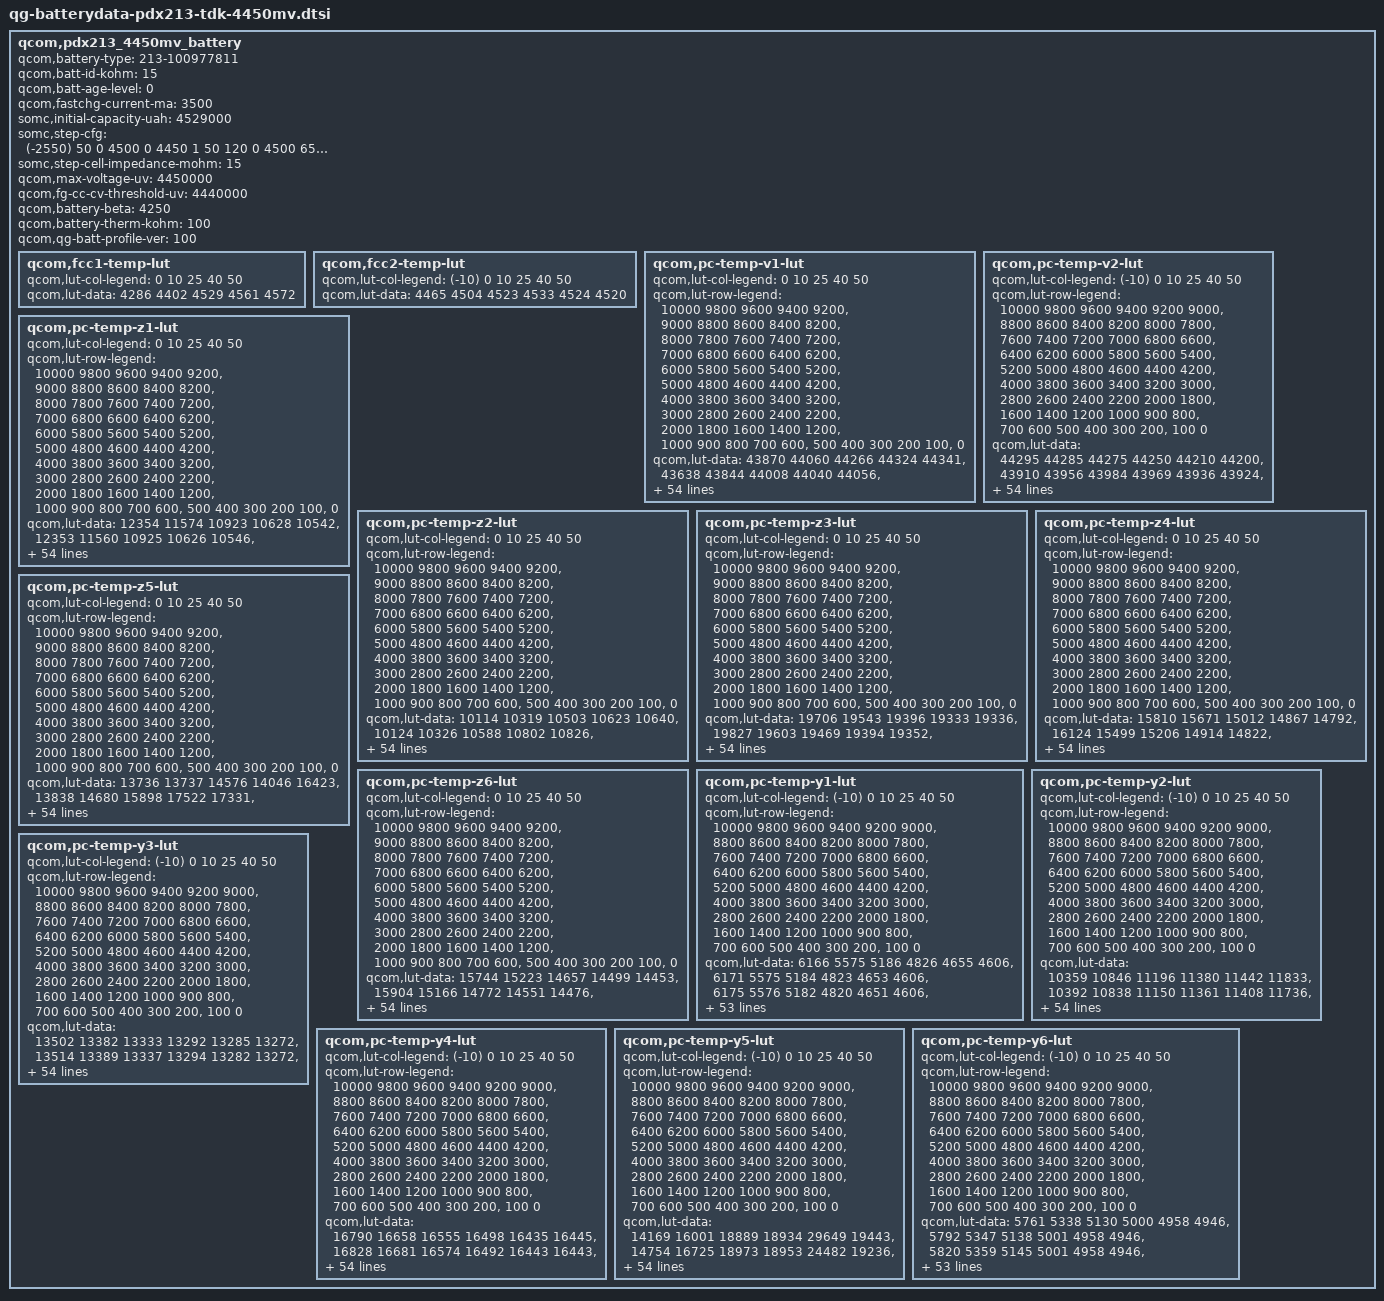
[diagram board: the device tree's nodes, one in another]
qcom,pdx213_4450mv_battery {
	/* Added or Modified by SOMC */
	qcom,battery-type = "213-100977811";
	qcom,batt-id-kohm = <15>;
	qcom,batt-age-level = <0>;
	qcom,fastchg-current-ma = <3500>;
	somc,initial-capacity-uah = <4529000>;
	somc,step-cfg = <
		(-2550) 50    0 4500    0 4450 1
		   50  120    0 4500  650 4450 2
		  120  150    0 4100 2150 4450 3
		  120  150 4100 4200 1750 4450 3
		  120  150 4200 4300 1300 4450 3
		  120  150 4300 4500  850 4450 3
		  150  200    0 4100 2600 4450 3
		  150  200 4100 4200 2150 4450 3
		  150  200 4200 4300 1750 4450 3
		  150  200 4300 4500 1300 4450 3
		  200  450    0 4200 4450 4450 3
		  200  450 4200 4250 3250 4450 3
		  200  450 4250 4350 1950 4450 3
		  200  450 4350 4500 1300 4450 3
		  450  550    0 4500 1300 4200 4
		  550 2550    0 4500    0 4200 5
	>;
	somc,step-cell-impedance-mohm = <15>;

	/* Prepared by Qualcomm */
    /* 4764064_SoMC_Licht_4468mAh_averaged_MasterSlave_Sept10th2020 */
    qcom,max-voltage-uv = <4450000>;
    qcom,fg-cc-cv-threshold-uv = <4440000>;
    /* qcom,fastchg-current-ma = <1500>; */
    /* qcom,batt-id-kohm = <0>; */
    qcom,battery-beta = <4250>;
    qcom,battery-therm-kohm = <100>;
    /* qcom,battery-type = "4764064_SoMC_Licht_4468mAh_averaged_MasterSlave_Sept10th2020"; */
    qcom,qg-batt-profile-ver = <100>;

	qcom,fcc1-temp-lut {
		qcom,lut-col-legend = <0 10 25 40 50>;
		qcom,lut-data = <4286 4402 4529 4561 4572>;
	};

	qcom,fcc2-temp-lut {
		qcom,lut-col-legend = <(-10) 0 10 25 40 50>;
		qcom,lut-data = <4465 4504 4523 4533 4524 4520>;
	};

	qcom,pc-temp-v1-lut {
		qcom,lut-col-legend = <0 10 25 40 50>;
		qcom,lut-row-legend = <10000 9800 9600 9400 9200>,
			<9000 8800 8600 8400 8200>,
			<8000 7800 7600 7400 7200>,
			<7000 6800 6600 6400 6200>,
			<6000 5800 5600 5400 5200>,
			<5000 4800 4600 4400 4200>,
			<4000 3800 3600 3400 3200>,
			<3000 2800 2600 2400 2200>,
			<2000 1800 1600 1400 1200>,
			<1000 900 800 700 600>,
			<500 400 300 200 100>,
			<0>;
		qcom,lut-data = <43870 44060 44266 44324 44341>,
			<43638 43844 44008 44040 44056>,
			<43413 43623 43791 43817 43826>,
			<43187 43398 43582 43607 43615>,
			<42953 43168 43358 43388 43397>,
			<42714 42933 43127 43162 43175>,
			<42478 42694 42891 42931 42948>,
			<42243 42454 42646 42692 42711>,
			<42014 42215 42399 42450 42470>,
			<41794 41976 42157 42208 42229>,
			<41580 41745 41918 41967 41990>,
			<41369 41519 41682 41729 41753>,
			<41157 41299 41450 41498 41521>,
			<40949 41087 41224 41270 41291>,
			<40744 40881 41006 41047 41068>,
			<40539 40679 40795 40830 40850>,
			<40347 40481 40593 40623 40641>,
			<40174 40295 40397 40425 40441>,
			<40014 40131 40212 40237 40250>,
			<39860 39976 40047 40063 40073>,
			<39719 39806 39881 39898 39906>,
			<39572 39621 39671 39704 39717>,
			<39393 39425 39407 39464 39488>,
			<39180 39192 39184 39237 39265>,
			<38993 38950 39021 39056 39077>,
			<38841 38807 38885 38899 38910>,
			<38714 38731 38767 38768 38772>,
			<38628 38666 38666 38657 38660>,
			<38569 38591 38573 38557 38558>,
			<38520 38515 38485 38461 38460>,
			<38473 38445 38407 38374 38370>,
			<38430 38377 38337 38296 38287>,
			<38387 38318 38276 38225 38210>,
			<38343 38267 38220 38161 38140>,
			<38301 38224 38170 38107 38080>,
			<38264 38183 38122 38056 38023>,
			<38230 38149 38076 38003 37957>,
			<38189 38111 38032 37947 37885>,
			<38125 38050 37973 37881 37807>,
			<38040 37958 37891 37800 37727>,
			<37939 37852 37791 37704 37637>,
			<37812 37732 37676 37590 37523>,
			<37667 37592 37540 37453 37383>,
			<37498 37422 37374 37296 37221>,
			<37338 37258 37211 37142 37073>,
			<37228 37147 37096 37034 36974>,
			<37190 37114 37070 37007 36948>,
			<37158 37094 37048 36992 36931>,
			<37130 37071 37033 36975 36915>,
			<37091 37043 37008 36947 36887>,
			<36980 36930 36866 36774 36691>,
			<36582 36519 36466 36364 36279>,
			<36014 35953 35907 35802 35722>,
			<35233 35174 35143 35039 34962>,
			<33896 33885 33973 33871 33803>,
			<30000 30000 30000 30000 30000>;
	};

	qcom,pc-temp-v2-lut {
		qcom,lut-col-legend = <(-10) 0 10 25 40 50>;
		qcom,lut-row-legend = <10000 9800 9600 9400 9200 9000>,
			<8800 8600 8400 8200 8000 7800>,
			<7600 7400 7200 7000 6800 6600>,
			<6400 6200 6000 5800 5600 5400>,
			<5200 5000 4800 4600 4400 4200>,
			<4000 3800 3600 3400 3200 3000>,
			<2800 2600 2400 2200 2000 1800>,
			<1600 1400 1200 1000 900 800>,
			<700 600 500 400 300 200>,
			<100 0>;
		qcom,lut-data = <44295 44285 44275 44250 44210 44200>,
			<43910 43956 43984 43969 43936 43924>,
			<43570 43657 43714 43706 43677 43665>,
			<43284 43395 43469 43465 43437 43426>,
			<43046 43167 43249 43246 43216 43207>,
			<42811 42939 43025 43023 42992 42985>,
			<42555 42694 42787 42785 42758 42751>,
			<42299 42446 42544 42543 42520 42513>,
			<42069 42202 42300 42301 42281 42275>,
			<41864 41959 42054 42059 42040 42034>,
			<41649 41726 41813 41820 41803 41798>,
			<41394 41503 41578 41583 41568 41566>,
			<41129 41287 41349 41351 41338 41338>,
			<40905 41078 41126 41125 41113 41114>,
			<40716 40874 40909 40906 40893 40895>,
			<40505 40661 40701 40693 40682 40683>,
			<40209 40431 40508 40485 40478 40478>,
			<39885 40190 40313 40285 40282 40280>,
			<39632 39944 40097 40103 40097 40096>,
			<39432 39692 39866 39930 39920 39920>,
			<39238 39457 39633 39733 39732 39736>,
			<39024 39246 39391 39494 39525 39535>,
			<38813 39050 39164 39255 39313 39329>,
			<38628 38871 38975 39047 39099 39116>,
			<38455 38706 38809 38855 38886 38899>,
			<38323 38555 38661 38700 38722 38732>,
			<38236 38415 38529 38575 38599 38610>,
			<38169 38286 38410 38465 38494 38504>,
			<38105 38166 38302 38363 38392 38402>,
			<38046 38055 38203 38268 38298 38307>,
			<37989 37978 38110 38181 38213 38220>,
			<37933 37927 38019 38098 38136 38141>,
			<37877 37886 37938 38023 38063 38067>,
			<37818 37848 37870 37958 37996 38000>,
			<37757 37814 37810 37898 37932 37936>,
			<37691 37773 37765 37836 37855 37851>,
			<37621 37726 37732 37772 37763 37735>,
			<37545 37669 37695 37702 37667 37617>,
			<37464 37596 37643 37620 37573 37519>,
			<37377 37505 37578 37531 37478 37426>,
			<37288 37409 37493 37439 37383 37331>,
			<37199 37304 37374 37341 37288 37234>,
			<37112 37172 37240 37221 37172 37118>,
			<37026 37005 37085 37077 37034 36980>,
			<36936 36864 36911 36928 36893 36843>,
			<36840 36761 36822 36876 36853 36803>,
			<36784 36722 36781 36859 36843 36791>,
			<36728 36681 36751 36839 36827 36777>,
			<36664 36635 36701 36814 36803 36753>,
			<36592 36570 36623 36748 36753 36697>,
			<36473 36405 36427 36520 36516 36428>,
			<36241 35989 35970 36028 36026 35942>,
			<35773 35307 35292 35376 35387 35302>,
			<34992 34239 34342 34452 34499 34413>,
			<33721 32619 32836 33194 33238 33170>,
			<31966 29644 29516 29584 29644 29828>;
	};

	qcom,pc-temp-z1-lut {
		qcom,lut-col-legend = <0 10 25 40 50>;
		qcom,lut-row-legend = <10000 9800 9600 9400 9200>,
			<9000 8800 8600 8400 8200>,
			<8000 7800 7600 7400 7200>,
			<7000 6800 6600 6400 6200>,
			<6000 5800 5600 5400 5200>,
			<5000 4800 4600 4400 4200>,
			<4000 3800 3600 3400 3200>,
			<3000 2800 2600 2400 2200>,
			<2000 1800 1600 1400 1200>,
			<1000 900 800 700 600>,
			<500 400 300 200 100>,
			<0>;
		qcom,lut-data = <12354 11574 10923 10628 10542>,
			<12353 11560 10925 10626 10546>,
			<12345 11549 10916 10623 10545>,
			<12335 11541 10908 10619 10544>,
			<12321 11532 10900 10616 10543>,
			<12302 11519 10894 10614 10541>,
			<12284 11499 10888 10612 10540>,
			<12263 11488 10883 10609 10540>,
			<12243 11485 10878 10607 10539>,
			<12225 11483 10873 10605 10538>,
			<12204 11480 10869 10603 10537>,
			<12195 11476 10866 10601 10537>,
			<12199 11471 10864 10601 10536>,
			<12203 11467 10863 10600 10536>,
			<12202 11462 10862 10600 10536>,
			<12192 11459 10861 10601 10537>,
			<12185 11456 10861 10601 10538>,
			<12185 11454 10864 10602 10539>,
			<12186 11457 10866 10603 10540>,
			<12189 11463 10868 10604 10541>,
			<12206 11467 10870 10605 10541>,
			<12225 11473 10873 10607 10542>,
			<12229 11480 10875 10609 10544>,
			<12230 11489 10878 10612 10547>,
			<12228 11499 10883 10616 10550>,
			<12225 11502 10888 10619 10553>,
			<12222 11498 10893 10622 10556>,
			<12226 11495 10898 10625 10558>,
			<12252 11497 10904 10628 10560>,
			<12275 11504 10909 10630 10562>,
			<12275 11510 10914 10633 10564>,
			<12267 11518 10917 10635 10566>,
			<12266 11525 10919 10637 10568>,
			<12272 11526 10922 10639 10570>,
			<12278 11525 10926 10642 10571>,
			<12286 11526 10930 10646 10573>,
			<12299 11532 10936 10649 10575>,
			<12307 11541 10944 10652 10578>,
			<12312 11549 10949 10655 10580>,
			<12321 11559 10953 10658 10581>,
			<12327 11567 10957 10661 10583>,
			<12335 11574 10964 10664 10585>,
			<12351 11582 10972 10666 10587>,
			<12389 11598 10981 10669 10589>,
			<12380 11607 10986 10673 10591>,
			<12394 11612 10988 10675 10592>,
			<12375 11608 10987 10674 10593>,
			<12388 11614 10990 10676 10593>,
			<12414 11615 10994 10676 10594>,
			<12392 11622 10997 10678 10596>,
			<12418 11641 11006 10683 10600>,
			<12468 11656 11020 10691 10607>,
			<12456 11686 11039 10704 10617>,
			<12515 11722 11075 10724 10633>,
			<12515 11722 11075 10724 10633>,
			<12515 11722 11075 10724 10633>;
	};

	qcom,pc-temp-z2-lut {
		qcom,lut-col-legend = <0 10 25 40 50>;
		qcom,lut-row-legend = <10000 9800 9600 9400 9200>,
			<9000 8800 8600 8400 8200>,
			<8000 7800 7600 7400 7200>,
			<7000 6800 6600 6400 6200>,
			<6000 5800 5600 5400 5200>,
			<5000 4800 4600 4400 4200>,
			<4000 3800 3600 3400 3200>,
			<3000 2800 2600 2400 2200>,
			<2000 1800 1600 1400 1200>,
			<1000 900 800 700 600>,
			<500 400 300 200 100>,
			<0>;
		qcom,lut-data = <10114 10319 10503 10623 10640>,
			<10124 10326 10588 10802 10826>,
			<10103 10325 10551 10764 10875>,
			<10082 10294 10521 10736 10852>,
			<10070 10250 10500 10725 10841>,
			<10060 10226 10483 10726 10847>,
			<10055 10207 10479 10730 10851>,
			<10054 10201 10490 10728 10855>,
			<10053 10221 10506 10725 10865>,
			<10082 10253 10619 10832 10862>,
			<10174 10272 10796 11141 10820>,
			<10222 10284 10808 11261 10788>,
			<10173 10297 10655 11200 10753>,
			<10105 10312 10559 11129 10717>,
			<10096 10328 10656 11139 10720>,
			<10109 10344 10808 11183 10736>,
			<10126 10362 10867 11171 10743>,
			<10147 10375 10896 10886 10759>,
			<10171 10381 10907 10651 10779>,
			<10187 10386 10795 10646 10785>,
			<10195 10394 10648 10645 10797>,
			<10202 10409 10648 10665 10826>,
			<10215 10419 10699 10811 10987>,
			<10235 10414 10724 10942 11123>,
			<10255 10403 10682 10979 11094>,
			<10278 10401 10630 11000 11006>,
			<10297 10412 10635 10979 10922>,
			<10302 10422 10672 10841 10832>,
			<10301 10423 10688 10736 10754>,
			<10300 10423 10636 10708 10692>,
			<10301 10424 10579 10691 10646>,
			<10302 10432 10579 10696 10648>,
			<10305 10442 10595 10731 10701>,
			<10312 10453 10615 10769 10758>,
			<10322 10470 10649 10805 10806>,
			<10330 10483 10684 10844 10859>,
			<10336 10491 10703 10887 10944>,
			<10343 10499 10718 10935 11076>,
			<10354 10515 10742 10975 11127>,
			<10365 10537 10792 11016 11100>,
			<10366 10546 10831 11049 11072>,
			<10357 10540 10830 11075 11084>,
			<10354 10536 10823 11103 11114>,
			<10367 10544 10830 11014 11129>,
			<10551 10626 10855 10963 11128>,
			<10413 10678 10873 10981 11112>,
			<10296 10678 10844 10963 11105>,
			<10220 10754 10844 10968 11079>,
			<10022 10876 10806 10960 11119>,
			<9925 11054 10791 11025 11252>,
			<9804 11065 10963 10954 10880>,
			<9727 10951 11005 10765 10725>,
			<9593 10826 10893 10705 10675>,
			<9633 10645 10817 10625 10595>,
			<9633 10645 10817 10625 10595>,
			<9633 10645 10817 10625 10595>;
	};

	qcom,pc-temp-z3-lut {
		qcom,lut-col-legend = <0 10 25 40 50>;
		qcom,lut-row-legend = <10000 9800 9600 9400 9200>,
			<9000 8800 8600 8400 8200>,
			<8000 7800 7600 7400 7200>,
			<7000 6800 6600 6400 6200>,
			<6000 5800 5600 5400 5200>,
			<5000 4800 4600 4400 4200>,
			<4000 3800 3600 3400 3200>,
			<3000 2800 2600 2400 2200>,
			<2000 1800 1600 1400 1200>,
			<1000 900 800 700 600>,
			<500 400 300 200 100>,
			<0>;
		qcom,lut-data = <19706 19543 19396 19333 19336>,
			<19827 19603 19469 19394 19352>,
			<19866 19639 19491 19410 19376>,
			<19883 19658 19499 19417 19384>,
			<19891 19669 19498 19417 19385>,
			<19896 19669 19493 19411 19379>,
			<19896 19662 19488 19405 19373>,
			<19886 19653 19479 19398 19370>,
			<19874 19639 19473 19392 19367>,
			<19868 19624 19473 19392 19365>,
			<19861 19613 19476 19397 19358>,
			<19854 19605 19470 19398 19353>,
			<19833 19598 19448 19388 19348>,
			<19808 19593 19434 19378 19343>,
			<19804 19587 19438 19374 19341>,
			<19805 19581 19444 19373 19340>,
			<19806 19574 19444 19369 19338>,
			<19795 19569 19442 19352 19333>,
			<19771 19566 19439 19339 19328>,
			<19763 19564 19429 19338 19325>,
			<19763 19564 19419 19337 19323>,
			<19765 19569 19423 19339 19322>,
			<19769 19576 19445 19350 19329>,
			<19778 19581 19457 19363 19339>,
			<19783 19587 19438 19372 19357>,
			<19781 19588 19414 19380 19379>,
			<19778 19578 19419 19387 19384>,
			<19774 19569 19445 19393 19376>,
			<19769 19574 19460 19396 19367>,
			<19763 19585 19463 19394 19361>,
			<19757 19588 19464 19389 19355>,
			<19751 19588 19460 19383 19350>,
			<19746 19586 19449 19376 19346>,
			<19743 19582 19441 19369 19341>,
			<19740 19575 19436 19362 19334>,
			<19735 19568 19431 19356 19328>,
			<19729 19563 19428 19352 19328>,
			<19723 19557 19425 19350 19329>,
			<19716 19553 19422 19348 19330>,
			<19709 19548 19419 19348 19327>,
			<19700 19543 19415 19349 19325>,
			<19689 19537 19410 19349 19326>,
			<19674 19529 19406 19350 19329>,
			<19651 19521 19403 19344 19335>,
			<19560 19497 19396 19337 19333>,
			<19422 19474 19387 19336 19319>,
			<19354 19468 19381 19336 19316>,
			<19330 19434 19384 19328 19316>,
			<19296 19386 19375 19327 19314>,
			<19290 19328 19368 19323 19302>,
			<19267 19325 19358 19339 19335>,
			<19268 19328 19351 19349 19340>,
			<19277 19322 19351 19356 19340>,
			<19316 19327 19360 19359 19344>,
			<19316 19327 19360 19359 19344>,
			<19316 19327 19360 19359 19344>;
	};

	qcom,pc-temp-z4-lut {
		qcom,lut-col-legend = <0 10 25 40 50>;
		qcom,lut-row-legend = <10000 9800 9600 9400 9200>,
			<9000 8800 8600 8400 8200>,
			<8000 7800 7600 7400 7200>,
			<7000 6800 6600 6400 6200>,
			<6000 5800 5600 5400 5200>,
			<5000 4800 4600 4400 4200>,
			<4000 3800 3600 3400 3200>,
			<3000 2800 2600 2400 2200>,
			<2000 1800 1600 1400 1200>,
			<1000 900 800 700 600>,
			<500 400 300 200 100>,
			<0>;
		qcom,lut-data = <15810 15671 15012 14867 14792>,
			<16124 15499 15206 14914 14822>,
			<15890 15353 15110 14895 14825>,
			<15634 15224 14993 14841 14786>,
			<15479 15116 14921 14808 14764>,
			<15350 15036 14864 14785 14753>,
			<15250 14971 14834 14770 14745>,
			<15174 14926 14820 14762 14738>,
			<15109 14898 14807 14757 14732>,
			<15034 14878 14782 14743 14727>,
			<14952 14863 14754 14719 14721>,
			<14912 14852 14747 14706 14717>,
			<14916 14841 14756 14702 14712>,
			<14926 14830 14759 14699 14705>,
			<14926 14821 14742 14691 14697>,
			<14921 14821 14718 14680 14687>,
			<14918 14829 14709 14676 14679>,
			<14917 14834 14703 14684 14673>,
			<14917 14818 14700 14692 14668>,
			<14914 14790 14702 14687 14663>,
			<14888 14786 14709 14680 14658>,
			<14859 14803 14732 14685 14661>,
			<14874 14832 14801 14745 14713>,
			<14941 14898 14858 14795 14759>,
			<14999 14991 14893 14799 14755>,
			<15034 15014 14916 14797 14740>,
			<15060 14984 14904 14788 14729>,
			<15063 14945 14853 14761 14720>,
			<15045 14914 14814 14737 14713>,
			<15021 14884 14791 14723 14705>,
			<15000 14868 14775 14713 14698>,
			<14979 14860 14768 14705 14690>,
			<14962 14855 14763 14699 14682>,
			<14948 14851 14760 14697 14677>,
			<14936 14848 14758 14696 14675>,
			<14924 14844 14757 14696 14673>,
			<14912 14837 14758 14700 14678>,
			<14900 14830 14762 14712 14695>,
			<14890 14826 14766 14719 14703>,
			<14879 14824 14772 14723 14702>,
			<14865 14820 14776 14725 14700>,
			<14846 14801 14766 14720 14696>,
			<14826 14778 14748 14711 14689>,
			<14805 14761 14740 14715 14689>,
			<14794 14728 14723 14713 14688>,
			<14905 14710 14705 14697 14685>,
			<14974 14706 14695 14687 14678>,
			<14992 14725 14674 14674 14660>,
			<15019 14768 14663 14651 14640>,
			<15017 14828 14661 14647 14641>,
			<15037 14832 14691 14658 14640>,
			<15051 14841 14709 14655 14642>,
			<15054 14853 14710 14649 14643>,
			<15032 14854 14698 14647 14640>,
			<15032 14854 14698 14647 14640>,
			<15032 14854 14698 14647 14640>;
	};

	qcom,pc-temp-z5-lut {
		qcom,lut-col-legend = <0 10 25 40 50>;
		qcom,lut-row-legend = <10000 9800 9600 9400 9200>,
			<9000 8800 8600 8400 8200>,
			<8000 7800 7600 7400 7200>,
			<7000 6800 6600 6400 6200>,
			<6000 5800 5600 5400 5200>,
			<5000 4800 4600 4400 4200>,
			<4000 3800 3600 3400 3200>,
			<3000 2800 2600 2400 2200>,
			<2000 1800 1600 1400 1200>,
			<1000 900 800 700 600>,
			<500 400 300 200 100>,
			<0>;
		qcom,lut-data = <13736 13737 14576 14046 16423>,
			<13838 14680 15898 17522 17331>,
			<14275 15516 16641 18365 19300>,
			<14786 16262 17216 19151 20652>,
			<15295 16931 17959 19641 21293>,
			<15854 17512 18677 20175 21458>,
			<16391 18031 18976 20456 21409>,
			<16857 18511 19175 20148 21380>,
			<17383 19082 19321 19749 21484>,
			<18355 19563 20155 20391 21522>,
			<19896 19765 21506 22485 21124>,
			<20737 20061 21513 23317 20774>,
			<20735 20361 19995 22606 20431>,
			<20654 20851 19007 21780 20208>,
			<21143 21373 20240 22388 20749>,
			<23301 21430 22310 24108 21823>,
			<24949 21259 23274 24388 22266>,
			<24083 21145 23969 21198 22052>,
			<22131 21561 24497 18494 21820>,
			<21516 22605 24262 18757 22131>,
			<23565 24198 23908 19696 23012>,
			<26841 27507 26062 20826 23300>,
			<30407 29762 33027 22619 22765>,
			<34879 29569 36472 23760 22103>,
			<37018 28937 28793 21749 21403>,
			<36079 27986 19227 18200 20514>,
			<34288 24933 18445 17645 20248>,
			<32703 22447 19692 18904 20166>,
			<30914 23028 21262 20424 20135>,
			<29555 24953 23634 21838 20404>,
			<28998 26934 25960 23307 21058>,
			<28625 29288 27126 24705 22025>,
			<28556 31103 27973 26109 23744>,
			<29236 31620 28865 27207 25109>,
			<30075 31925 30351 28114 26021>,
			<30355 31957 31538 28700 26646>,
			<30492 31635 31740 28341 26594>,
			<30649 31292 31649 26879 26136>,
			<30969 31225 31151 25550 25461>,
			<31309 31208 28877 24228 23738>,
			<31196 31157 26767 23344 22232>,
			<29718 30497 26312 23555 22596>,
			<28093 29686 26000 23989 23609>,
			<26484 29069 25031 21355 24060>,
			<21192 29332 24790 19653 22600>,
			<14877 26855 25358 19952 18694>,
			<12333 25131 24325 20999 18708>,
			<11975 18607 27531 20825 20590>,
			<11599 15941 25277 24675 25560>,
			<11535 12637 23634 24698 21719>,
			<11341 12601 18702 22177 28754>,
			<11316 12613 16049 22989 28509>,
			<11294 12341 15668 25424 26528>,
			<11921 12594 16295 25418 27773>,
			<11921 12594 16295 25418 27773>,
			<11921 12594 16295 25418 27773>;
	};

	qcom,pc-temp-z6-lut {
		qcom,lut-col-legend = <0 10 25 40 50>;
		qcom,lut-row-legend = <10000 9800 9600 9400 9200>,
			<9000 8800 8600 8400 8200>,
			<8000 7800 7600 7400 7200>,
			<7000 6800 6600 6400 6200>,
			<6000 5800 5600 5400 5200>,
			<5000 4800 4600 4400 4200>,
			<4000 3800 3600 3400 3200>,
			<3000 2800 2600 2400 2200>,
			<2000 1800 1600 1400 1200>,
			<1000 900 800 700 600>,
			<500 400 300 200 100>,
			<0>;
		qcom,lut-data = <15744 15223 14657 14499 14453>,
			<15904 15166 14772 14551 14476>,
			<15798 15111 14738 14548 14487>,
			<15678 15056 14695 14531 14477>,
			<15594 15004 14663 14517 14468>,
			<15519 14961 14634 14504 14460>,
			<15455 14923 14615 14494 14454>,
			<15401 14893 14603 14486 14449>,
			<15353 14869 14593 14480 14445>,
			<15308 14850 14582 14473 14440>,
			<15264 14836 14572 14467 14435>,
			<15237 14824 14563 14460 14429>,
			<15224 14814 14555 14453 14424>,
			<15215 14804 14548 14446 14419>,
			<15210 14796 14542 14441 14414>,
			<15207 14793 14536 14435 14409>,
			<15204 14792 14532 14431 14404>,
			<15197 14791 14528 14426 14399>,
			<15188 14783 14526 14421 14394>,
			<15179 14771 14523 14418 14391>,
			<15171 14770 14521 14415 14387>,
			<15166 14781 14531 14418 14388>,
			<15175 14800 14577 14451 14414>,
			<15212 14834 14604 14480 14441>,
			<15242 14878 14608 14488 14450>,
			<15258 14889 14610 14493 14455>,
			<15268 14872 14608 14492 14455>,
			<15270 14853 14601 14485 14448>,
			<15262 14845 14594 14477 14440>,
			<15253 14839 14588 14470 14433>,
			<15244 14836 14582 14463 14427>,
			<15235 14834 14575 14457 14421>,
			<15227 14833 14568 14451 14415>,
			<15222 14830 14564 14446 14410>,
			<15217 14827 14560 14441 14405>,
			<15213 14823 14558 14438 14401>,
			<15208 14820 14558 14439 14403>,
			<15207 14817 14560 14442 14411>,
			<15209 14817 14561 14445 14415>,
			<15212 14817 14562 14447 14413>,
			<15212 14817 14563 14448 14412>,
			<15208 14811 14558 14447 14411>,
			<15202 14804 14550 14444 14410>,
			<15193 14799 14547 14442 14413>,
			<15155 14782 14538 14438 14412>,
			<15143 14767 14527 14431 14403>,
			<15141 14763 14519 14427 14399>,
			<15140 14756 14513 14417 14391>,
			<15140 14753 14504 14407 14382>,
			<15147 14753 14501 14403 14376>,
			<15157 14762 14511 14418 14393>,
			<15180 14776 14519 14423 14398>,
			<15203 14789 14524 14427 14401>,
			<15243 14812 14531 14431 14405>,
			<15243 14812 14531 14431 14405>,
			<15243 14812 14531 14431 14405>;
	};

	qcom,pc-temp-y1-lut {
		qcom,lut-col-legend = <(-10) 0 10 25 40 50>;
		qcom,lut-row-legend = <10000 9800 9600 9400 9200 9000>,
			<8800 8600 8400 8200 8000 7800>,
			<7600 7400 7200 7000 6800 6600>,
			<6400 6200 6000 5800 5600 5400>,
			<5200 5000 4800 4600 4400 4200>,
			<4000 3800 3600 3400 3200 3000>,
			<2800 2600 2400 2200 2000 1800>,
			<1600 1400 1200 1000 900 800>,
			<700 600 500 400 300 200>,
			<100 0>;
		qcom,lut-data = <6166 5575 5186 4826 4655 4606>,
			<6171 5575 5184 4823 4653 4606>,
			<6175 5576 5182 4820 4651 4606>,
			<6176 5577 5179 4817 4649 4605>,
			<6177 5579 5176 4813 4648 4605>,
			<6178 5581 5173 4811 4646 4605>,
			<6175 5587 5169 4808 4645 4604>,
			<6171 5594 5166 4805 4644 4604>,
			<6170 5592 5165 4802 4643 4603>,
			<6177 5577 5166 4800 4642 4603>,
			<6181 5569 5166 4797 4642 4603>,
			<6174 5569 5166 4796 4640 4603>,
			<6164 5571 5165 4794 4639 4603>,
			<6165 5574 5162 4793 4639 4603>,
			<6180 5582 5154 4792 4639 4602>,
			<6190 5587 5151 4791 4639 4601>,
			<6192 5587 5152 4791 4639 4601>,
			<6193 5587 5153 4792 4639 4601>,
			<6192 5587 5153 4792 4640 4602>,
			<6182 5587 5152 4792 4640 4603>,
			<6174 5588 5152 4792 4640 4604>,
			<6184 5589 5153 4794 4641 4604>,
			<6198 5591 5155 4797 4642 4604>,
			<6200 5593 5157 4799 4643 4605>,
			<6192 5599 5161 4801 4644 4607>,
			<6187 5601 5164 4803 4646 4608>,
			<6186 5598 5170 4805 4647 4608>,
			<6186 5594 5174 4808 4649 4608>,
			<6184 5594 5174 4811 4650 4609>,
			<6176 5592 5173 4815 4651 4610>,
			<6170 5592 5173 4818 4652 4612>,
			<6168 5592 5175 4822 4655 4612>,
			<6166 5593 5178 4825 4657 4613>,
			<6168 5595 5180 4828 4659 4615>,
			<6178 5598 5182 4831 4660 4617>,
			<6185 5600 5184 4834 4662 4619>,
			<6180 5601 5186 4837 4663 4620>,
			<6171 5601 5188 4839 4664 4621>,
			<6172 5605 5191 4841 4666 4622>,
			<6183 5612 5196 4844 4667 4623>,
			<6191 5614 5202 4847 4669 4624>,
			<6184 5611 5210 4852 4670 4624>,
			<6178 5610 5213 4856 4671 4625>,
			<6182 5609 5214 4860 4673 4626>,
			<6198 5614 5221 4863 4675 4627>,
			<6243 5628 5228 4865 4676 4627>,
			<6233 5631 5239 4868 4676 4629>,
			<6253 5632 5239 4872 4677 4629>,
			<6290 5645 5233 4876 4679 4630>,
			<6346 5656 5241 4878 4679 4630>,
			<6365 5695 5248 4879 4680 4631>,
			<6425 5731 5251 4888 4683 4634>,
			<6512 5777 5270 4906 4689 4638>,
			<6633 5915 5334 4929 4697 4645>,
			<6633 5915 5334 4929 4697 4645>,
			<6633 5915 5334 4929 4697 4645>;
	};

	qcom,pc-temp-y2-lut {
		qcom,lut-col-legend = <(-10) 0 10 25 40 50>;
		qcom,lut-row-legend = <10000 9800 9600 9400 9200 9000>,
			<8800 8600 8400 8200 8000 7800>,
			<7600 7400 7200 7000 6800 6600>,
			<6400 6200 6000 5800 5600 5400>,
			<5200 5000 4800 4600 4400 4200>,
			<4000 3800 3600 3400 3200 3000>,
			<2800 2600 2400 2200 2000 1800>,
			<1600 1400 1200 1000 900 800>,
			<700 600 500 400 300 200>,
			<100 0>;
		qcom,lut-data = <10359 10846 11196 11380 11442 11833>,
			<10392 10838 11150 11361 11408 11736>,
			<10434 10828 11104 11335 11374 11621>,
			<10477 10816 11061 11303 11342 11505>,
			<10514 10803 11021 11268 11314 11409>,
			<10538 10792 10986 11231 11293 11351>,
			<10551 10776 10953 11179 11279 11320>,
			<10562 10762 10925 11134 11267 11298>,
			<10579 10762 10905 11126 11256 11289>,
			<10629 10774 10888 11125 11242 11279>,
			<10666 10785 10882 11125 11237 11269>,
			<10699 10793 10893 11127 11248 11260>,
			<10743 10803 10911 11131 11261 11255>,
			<10746 10837 10928 11141 11261 11266>,
			<10726 10924 10949 11162 11255 11303>,
			<10720 10978 10976 11191 11254 11333>,
			<10759 10991 11028 11238 11291 11351>,
			<10811 10995 11086 11293 11353 11371>,
			<10829 11002 11132 11344 11421 11404>,
			<10837 11024 11175 11395 11506 11459>,
			<10838 11041 11195 11409 11588 11536>,
			<10658 11051 11198 11396 11680 11699>,
			<10341 11058 11201 11384 11739 11830>,
			<10180 11064 11212 11389 11694 11786>,
			<9891 11073 11233 11405 11575 11658>,
			<9713 11075 11248 11422 11529 11616>,
			<9697 11054 11258 11447 11544 11639>,
			<9688 11031 11267 11473 11571 11677>,
			<9682 11049 11284 11495 11595 11733>,
			<9679 11102 11303 11516 11623 11819>,
			<9676 11120 11307 11541 11661 11903>,
			<9673 11082 11297 11577 11736 11993>,
			<9671 11025 11286 11600 11816 12070>,
			<9669 10973 11283 11607 11894 12139>,
			<9668 10916 11280 11613 11964 12202>,
			<9666 10832 11270 11616 11969 12190>,
			<9665 10577 11236 11616 11905 12024>,
			<9665 10319 11194 11613 11841 11900>,
			<9664 10112 11156 11590 11782 11897>,
			<9663 9812 11113 11553 11722 11904>,
			<9662 9710 11056 11525 11709 11891>,
			<9662 9691 10977 11503 11707 11853>,
			<9661 9679 10887 11478 11719 11835>,
			<9660 9672 10785 11443 11732 11825>,
			<9659 9668 10623 11386 11681 11785>,
			<9658 9665 10582 11357 11543 11571>,
			<9657 9663 10296 11324 11507 11518>,
			<9655 9661 10125 11308 11473 11466>,
			<9653 9659 9861 11285 11443 11382>,
			<9651 9657 9756 11243 11492 11508>,
			<9650 9654 9696 11209 11471 11436>,
			<9649 9651 9672 11125 11341 11304>,
			<9648 9649 9659 11023 11253 11221>,
			<9648 9649 9657 10893 11168 11100>,
			<9648 9649 9657 10893 11168 11100>,
			<9648 9649 9657 10893 11168 11100>;
	};

	qcom,pc-temp-y3-lut {
		qcom,lut-col-legend = <(-10) 0 10 25 40 50>;
		qcom,lut-row-legend = <10000 9800 9600 9400 9200 9000>,
			<8800 8600 8400 8200 8000 7800>,
			<7600 7400 7200 7000 6800 6600>,
			<6400 6200 6000 5800 5600 5400>,
			<5200 5000 4800 4600 4400 4200>,
			<4000 3800 3600 3400 3200 3000>,
			<2800 2600 2400 2200 2000 1800>,
			<1600 1400 1200 1000 900 800>,
			<700 600 500 400 300 200>,
			<100 0>;
		qcom,lut-data = <13502 13382 13333 13292 13285 13272>,
			<13514 13389 13337 13294 13282 13272>,
			<13525 13397 13340 13295 13279 13272>,
			<13536 13406 13344 13297 13278 13273>,
			<13544 13413 13347 13299 13278 13273>,
			<13546 13417 13349 13300 13278 13274>,
			<13544 13419 13352 13300 13280 13275>,
			<13541 13420 13354 13300 13284 13276>,
			<13542 13420 13354 13301 13286 13276>,
			<13554 13419 13354 13302 13287 13277>,
			<13561 13418 13354 13303 13287 13278>,
			<13532 13422 13354 13303 13288 13281>,
			<13487 13427 13354 13303 13289 13284>,
			<13479 13424 13353 13304 13289 13284>,
			<13486 13410 13351 13307 13288 13285>,
			<13491 13401 13350 13308 13288 13285>,
			<13483 13403 13350 13307 13291 13285>,
			<13467 13405 13350 13305 13293 13284>,
			<13456 13401 13349 13305 13293 13284>,
			<13448 13391 13347 13306 13292 13286>,
			<13443 13382 13344 13306 13291 13286>,
			<13439 13377 13339 13304 13289 13285>,
			<13435 13372 13333 13302 13288 13283>,
			<13429 13368 13330 13298 13284 13279>,
			<13418 13364 13327 13295 13280 13274>,
			<13412 13360 13325 13293 13278 13273>,
			<13417 13358 13323 13292 13278 13274>,
			<13428 13356 13322 13292 13278 13274>,
			<13443 13347 13321 13292 13277 13274>,
			<13465 13331 13321 13293 13276 13273>,
			<13492 13326 13320 13293 13276 13273>,
			<13521 13330 13319 13292 13276 13273>,
			<13556 13336 13318 13292 13277 13274>,
			<13595 13344 13317 13292 13278 13274>,
			<13642 13353 13316 13292 13279 13275>,
			<13693 13361 13316 13292 13279 13275>,
			<13747 13367 13320 13293 13278 13273>,
			<13806 13373 13325 13294 13277 13272>,
			<13866 13384 13328 13292 13276 13272>,
			<13930 13403 13330 13290 13276 13272>,
			<13996 13426 13333 13290 13276 13273>,
			<14067 13458 13334 13291 13277 13274>,
			<14142 13497 13337 13292 13277 13275>,
			<14223 13547 13339 13292 13277 13276>,
			<14332 13622 13340 13292 13274 13271>,
			<14380 13667 13342 13294 13278 13274>,
			<14530 13755 13343 13295 13282 13276>,
			<14814 13867 13356 13298 13284 13281>,
			<15286 14028 13370 13306 13288 13283>,
			<16090 14279 13408 13311 13291 13284>,
			<17588 14848 13472 13310 13287 13281>,
			<21117 16276 13592 13308 13285 13281>,
			<31980 20965 13983 13318 13287 13282>,
			<65535 41282 15648 13327 13291 13285>,
			<65535 41282 15648 13327 13291 13285>,
			<65535 41282 15648 13327 13291 13285>;
	};

	qcom,pc-temp-y4-lut {
		qcom,lut-col-legend = <(-10) 0 10 25 40 50>;
		qcom,lut-row-legend = <10000 9800 9600 9400 9200 9000>,
			<8800 8600 8400 8200 8000 7800>,
			<7600 7400 7200 7000 6800 6600>,
			<6400 6200 6000 5800 5600 5400>,
			<5200 5000 4800 4600 4400 4200>,
			<4000 3800 3600 3400 3200 3000>,
			<2800 2600 2400 2200 2000 1800>,
			<1600 1400 1200 1000 900 800>,
			<700 600 500 400 300 200>,
			<100 0>;
		qcom,lut-data = <16790 16658 16555 16498 16435 16445>,
			<16828 16681 16574 16492 16443 16443>,
			<16910 16722 16594 16489 16448 16442>,
			<17007 16768 16613 16487 16451 16442>,
			<17087 16806 16626 16487 16452 16441>,
			<17122 16823 16631 16487 16453 16441>,
			<17122 16825 16627 16489 16450 16442>,
			<17122 16827 16621 16491 16447 16443>,
			<17122 16830 16621 16494 16447 16444>,
			<17126 16836 16622 16497 16450 16447>,
			<17131 16841 16625 16501 16454 16448>,
			<17166 16847 16634 16508 16458 16449>,
			<17221 16855 16649 16516 16463 16449>,
			<17236 16880 16665 16524 16470 16451>,
			<17219 16946 16684 16531 16478 16456>,
			<17189 16978 16706 16540 16486 16463>,
			<17089 16943 16740 16560 16492 16470>,
			<16953 16886 16765 16583 16498 16479>,
			<16897 16837 16757 16610 16513 16489>,
			<16873 16785 16722 16638 16539 16501>,
			<16849 16744 16683 16644 16548 16509>,
			<16806 16713 16635 16605 16545 16515>,
			<16764 16687 16593 16556 16540 16518>,
			<16752 16663 16569 16519 16515 16501>,
			<16750 16642 16553 16487 16467 16459>,
			<16751 16621 16544 16479 16452 16444>,
			<16759 16592 16539 16480 16454 16446>,
			<16770 16569 16536 16483 16458 16447>,
			<16772 16567 16535 16486 16464 16452>,
			<16769 16568 16534 16493 16474 16461>,
			<16768 16571 16531 16499 16484 16470>,
			<16769 16575 16521 16506 16494 16478>,
			<16771 16579 16512 16514 16503 16487>,
			<16772 16586 16511 16524 16509 16496>,
			<16775 16598 16512 16533 16514 16503>,
			<16777 16614 16517 16534 16512 16502>,
			<16777 16645 16535 16526 16498 16482>,
			<16777 16676 16556 16516 16483 16465>,
			<16778 16699 16577 16500 16471 16459>,
			<16778 16718 16597 16486 16463 16456>,
			<16779 16723 16601 16485 16461 16456>,
			<16783 16720 16602 16489 16463 16456>,
			<16790 16712 16603 16494 16463 16455>,
			<16798 16683 16603 16497 16463 16452>,
			<16814 16670 16583 16476 16445 16435>,
			<16787 16661 16569 16476 16447 16439>,
			<16820 16668 16595 16490 16453 16447>,
			<16887 16688 16623 16506 16462 16450>,
			<16996 16723 16664 16523 16477 16481>,
			<17188 16767 16710 16547 16518 16530>,
			<17550 16898 16744 16540 16493 16475>,
			<18402 17269 16744 16519 16451 16446>,
			<21794 19369 16835 16543 16459 16452>,
			<56069 43004 18161 16593 16484 16475>,
			<56069 43004 18161 16593 16484 16475>,
			<56069 43004 18161 16593 16484 16475>;
	};

	qcom,pc-temp-y5-lut {
		qcom,lut-col-legend = <(-10) 0 10 25 40 50>;
		qcom,lut-row-legend = <10000 9800 9600 9400 9200 9000>,
			<8800 8600 8400 8200 8000 7800>,
			<7600 7400 7200 7000 6800 6600>,
			<6400 6200 6000 5800 5600 5400>,
			<5200 5000 4800 4600 4400 4200>,
			<4000 3800 3600 3400 3200 3000>,
			<2800 2600 2400 2200 2000 1800>,
			<1600 1400 1200 1000 900 800>,
			<700 600 500 400 300 200>,
			<100 0>;
		qcom,lut-data = <14169 16001 18889 18934 29649 19443>,
			<14754 16725 18973 18953 24482 19236>,
			<15565 17359 18999 18857 20687 18941>,
			<16427 17862 18980 18666 18141 18624>,
			<17162 18191 18929 18399 16723 18347>,
			<17591 18303 18860 18072 16319 18173>,
			<17749 18158 18774 17419 17745 18039>,
			<17891 17913 18640 16654 19679 17865>,
			<18405 17720 18314 16262 19828 17591>,
			<20117 17423 17551 16013 19251 17132>,
			<21193 17282 16864 15709 18595 16935>,
			<19602 17950 16359 15126 17960 17985>,
			<17117 18834 15963 14629 17272 19284>,
			<17345 18755 15713 14626 16460 19200>,
			<21138 17976 15488 14751 15523 18271>,
			<23631 17624 15449 14784 15181 17308>,
			<22662 20441 16656 14394 15383 16265>,
			<21113 23887 18562 13994 15603 15483>,
			<20977 23941 20443 14326 15405 15398>,
			<21946 22827 22492 15571 14812 15397>,
			<22721 22313 23159 17286 14798 15555>,
			<21976 22597 23048 20674 18149 17873>,
			<20214 22936 22903 23203 21389 20175>,
			<18483 23010 22728 22749 21392 20170>,
			<14853 23042 22438 21491 20903 19788>,
			<12595 23212 22280 20802 20350 19611>,
			<12332 23957 22119 20436 19631 19817>,
			<12194 24646 22006 20267 18833 19992>,
			<12206 22489 22240 20489 17864 19133>,
			<12385 16447 22823 20920 16862 17364>,
			<12599 14132 23252 20995 16644 16832>,
			<12805 14518 23788 20733 16875 16862>,
			<13031 15197 24049 20540 17260 16924>,
			<13235 16342 22788 20924 18137 17380>,
			<13484 18036 20638 21789 19351 18190>,
			<13637 18909 20228 22847 19863 18505>,
			<13719 18615 20766 24387 20095 18585>,
			<13799 18087 21140 25144 20186 18680>,
			<13780 17245 20966 23517 19984 18986>,
			<13608 15623 20574 21011 19654 19515>,
			<13422 15212 20173 20037 19592 20161>,
			<13251 15397 19643 19581 19688 21050>,
			<13113 15291 19312 18951 19379 22035>,
			<13132 14346 19038 18618 18556 22734>,
			<13031 14049 18372 19871 18430 21029>,
			<13131 13777 18346 20489 18808 18678>,
			<12797 13978 16066 18569 18794 17431>,
			<12514 13773 15834 17410 17832 20905>,
			<12072 13658 14429 18029 19943 21218>,
			<11616 13746 14174 18907 21010 19197>,
			<10844 12997 14301 19478 19764 19673>,
			<9988 11205 14326 20408 22662 24179>,
			<9200 9666 13486 22075 23382 24375>,
			<8862 8933 10562 22344 26176 25751>,
			<8862 8933 10562 22344 26176 25751>,
			<8862 8933 10562 22344 26176 25751>;
	};

	qcom,pc-temp-y6-lut {
		qcom,lut-col-legend = <(-10) 0 10 25 40 50>;
		qcom,lut-row-legend = <10000 9800 9600 9400 9200 9000>,
			<8800 8600 8400 8200 8000 7800>,
			<7600 7400 7200 7000 6800 6600>,
			<6400 6200 6000 5800 5600 5400>,
			<5200 5000 4800 4600 4400 4200>,
			<4000 3800 3600 3400 3200 3000>,
			<2800 2600 2400 2200 2000 1800>,
			<1600 1400 1200 1000 900 800>,
			<700 600 500 400 300 200>,
			<100 0>;
		qcom,lut-data = <5761 5338 5130 5000 4958 4946>,
			<5792 5347 5138 5001 4958 4946>,
			<5820 5359 5145 5001 4958 4946>,
			<5844 5371 5149 5002 4958 4946>,
			<5860 5380 5151 5002 4958 4947>,
			<5866 5384 5152 5003 4958 4947>,
			<5859 5383 5150 5003 4959 4948>,
			<5848 5381 5147 5004 4961 4949>,
			<5848 5378 5145 5004 4962 4950>,
			<5857 5375 5144 5006 4963 4951>,
			<5862 5374 5144 5007 4965 4953>,
			<5853 5376 5145 5009 4966 4954>,
			<5838 5379 5148 5011 4968 4956>,
			<5835 5385 5150 5014 4970 4958>,
			<5842 5393 5153 5018 4972 4960>,
			<5845 5396 5157 5022 4975 4961>,
			<5818 5388 5166 5026 4978 4963>,
			<5774 5373 5174 5031 4981 4966>,
			<5759 5357 5171 5038 4986 4969>,
			<5754 5338 5159 5047 4992 4974>,
			<5749 5323 5146 5049 4994 4976>,
			<5737 5311 5129 5036 4992 4976>,
			<5723 5301 5113 5020 4989 4975>,
			<5717 5296 5104 5007 4979 4968>,
			<5716 5291 5098 4996 4962 4952>,
			<5719 5288 5096 4993 4957 4947>,
			<5734 5285 5095 4993 4957 4947>,
			<5759 5282 5095 4994 4958 4949>,
			<5784 5281 5095 4995 4960 4950>,
			<5810 5278 5097 4998 4962 4952>,
			<5840 5279 5097 5000 4965 4954>,
			<5873 5291 5096 5003 4968 4957>,
			<5909 5311 5095 5005 4971 4960>,
			<5950 5333 5095 5009 4974 4963>,
			<5996 5361 5097 5012 4976 4966>,
			<6044 5392 5101 5012 4976 4965>,
			<6092 5425 5113 5011 4971 4958>,
			<6141 5460 5127 5009 4966 4953>,
			<6193 5494 5142 5005 4963 4952>,
			<6248 5530 5158 5000 4960 4951>,
			<6307 5571 5173 5000 4960 4951>,
			<6370 5620 5188 5003 4961 4952>,
			<6438 5672 5208 5006 4962 4953>,
			<6515 5727 5231 5008 4962 4953>,
			<6623 5804 5244 5002 4954 4944>,
			<6677 5856 5254 5005 4958 4948>,
			<6828 5938 5285 5011 4963 4952>,
			<7114 6046 5332 5018 4967 4957>,
			<7550 6204 5385 5030 4974 4967>,
			<8279 6445 5462 5041 4988 4982>,
			<9567 6996 5563 5039 4978 4964>,
			<12441 8266 5715 5035 4965 4955>,
			<20950 12310 6137 5054 4969 4959>,
			<60070 32704 7889 5084 4981 4969>,
			<60070 32704 7889 5084 4981 4969>,
			<60070 32704 7889 5084 4981 4969>;
	};

};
